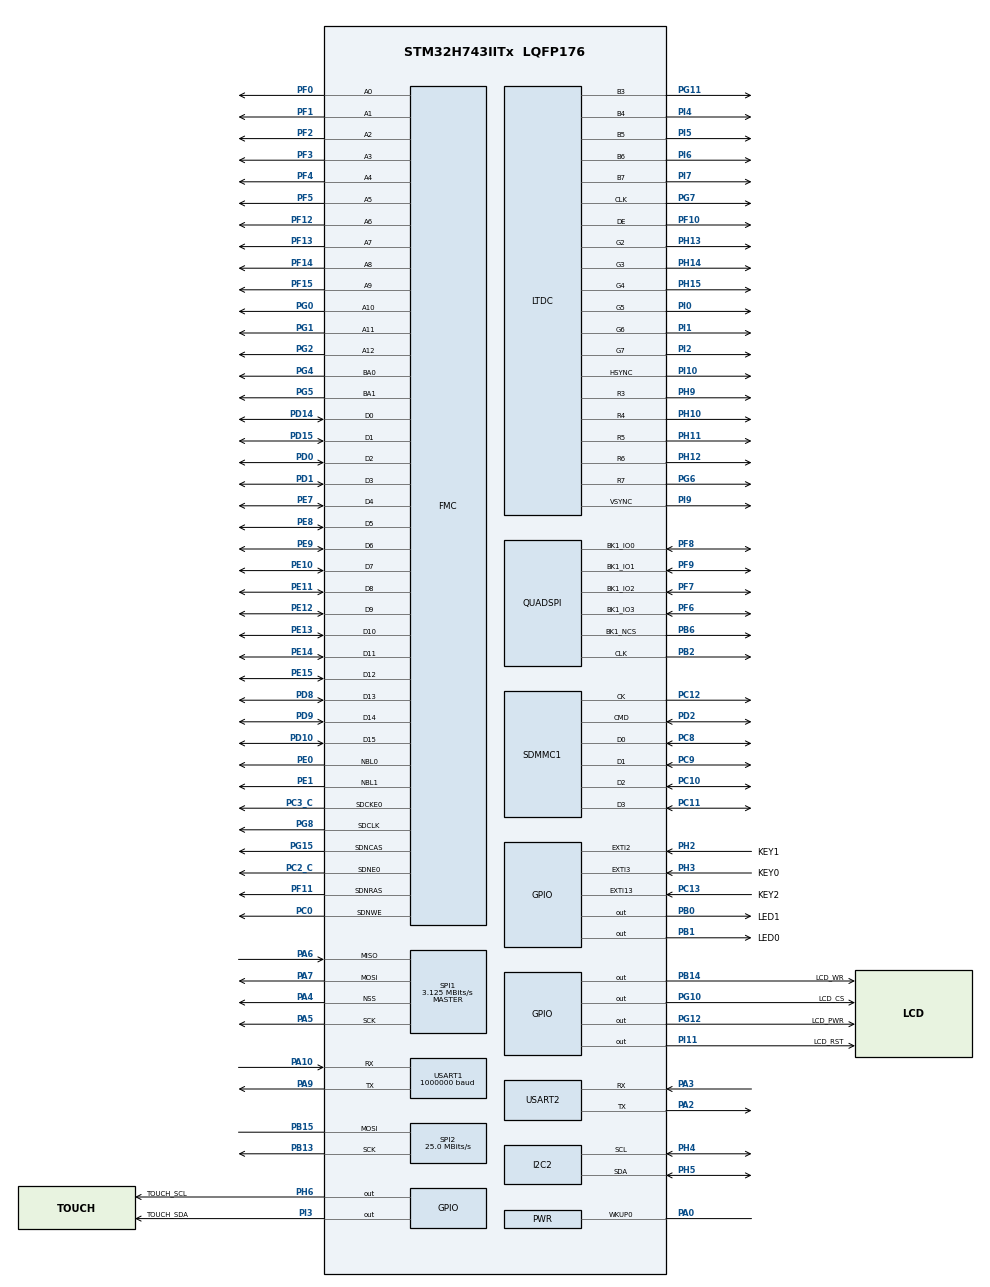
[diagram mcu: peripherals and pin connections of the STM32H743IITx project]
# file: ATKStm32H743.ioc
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CORTEX_M7.CPU_DCache=Enabled
CORTEX_M7.CPU_ICache=Enabled
Dma.I2C2_RX.0.Direction=DMA_PERIPH_TO_MEMORY
Dma.I2C2_RX.0.EventEnable=DISABLE
Dma.I2C2_RX.0.FIFOMode=DMA_FIFOMODE_DISABLE
Dma.I2C2_RX.0.Instance=DMA1_Stream2
Dma.I2C2_RX.0.MemDataAlignment=DMA_MDATAALIGN_BYTE
Dma.I2C2_RX.0.MemInc=DMA_MINC_ENABLE
Dma.I2C2_RX.0.Mode=DMA_NORMAL
Dma.I2C2_RX.0.PeriphDataAlignment=DMA_PDATAALIGN_BYTE
Dma.I2C2_RX.0.PeriphInc=DMA_PINC_DISABLE
Dma.I2C2_RX.0.Polarity=HAL_DMAMUX_REQ_GEN_RISING
Dma.I2C2_RX.0.Priority=DMA_PRIORITY_VERY_HIGH
Dma.I2C2_RX.0.RequestNumber=1
Dma.I2C2_RX.0.SignalID=NONE
Dma.I2C2_RX.0.SyncEnable=DISABLE
Dma.I2C2_RX.0.SyncPolarity=HAL_DMAMUX_SYNC_NO_EVENT
Dma.I2C2_RX.0.SyncRequestNumber=1
Dma.I2C2_RX.0.SyncSignalID=NONE
Dma.I2C2_TX.1.Direction=DMA_MEMORY_TO_PERIPH
Dma.I2C2_TX.1.EventEnable=DISABLE
Dma.I2C2_TX.1.FIFOMode=DMA_FIFOMODE_DISABLE
Dma.I2C2_TX.1.Instance=DMA1_Stream3
Dma.I2C2_TX.1.MemDataAlignment=DMA_MDATAALIGN_BYTE
Dma.I2C2_TX.1.MemInc=DMA_MINC_ENABLE
Dma.I2C2_TX.1.Mode=DMA_NORMAL
Dma.I2C2_TX.1.PeriphDataAlignment=DMA_PDATAALIGN_BYTE
Dma.I2C2_TX.1.PeriphInc=DMA_PINC_DISABLE
Dma.I2C2_TX.1.Polarity=HAL_DMAMUX_REQ_GEN_RISING
Dma.I2C2_TX.1.Priority=DMA_PRIORITY_LOW
Dma.I2C2_TX.1.RequestNumber=1
Dma.I2C2_TX.1.SignalID=NONE
Dma.I2C2_TX.1.SyncEnable=DISABLE
Dma.I2C2_TX.1.SyncPolarity=HAL_DMAMUX_SYNC_NO_EVENT
Dma.I2C2_TX.1.SyncRequestNumber=1
Dma.I2C2_TX.1.SyncSignalID=NONE
Dma.Request0=I2C2_RX
Dma.Request1=I2C2_TX
Dma.Request2=USART1_RX
Dma.Request3=USART1_TX
Dma.Request4=USART2_RX
Dma.Request5=USART2_TX
Dma.Request6=SPI2_RX
Dma.Request7=SPI2_TX
Dma.Request8=SPI1_RX
Dma.Request9=SPI1_TX
Dma.SPI1_RX.8.Direction=DMA_PERIPH_TO_MEMORY
Dma.SPI1_RX.8.EventEnable=DISABLE
Dma.SPI1_RX.8.FIFOMode=DMA_FIFOMODE_DISABLE
Dma.SPI1_RX.8.Instance=DMA2_Stream4
Dma.SPI1_RX.8.MemDataAlignment=DMA_MDATAALIGN_BYTE
Dma.SPI1_RX.8.MemInc=DMA_MINC_ENABLE
Dma.SPI1_RX.8.Mode=DMA_NORMAL
Dma.SPI1_RX.8.PeriphDataAlignment=DMA_PDATAALIGN_BYTE
Dma.SPI1_RX.8.PeriphInc=DMA_PINC_DISABLE
Dma.SPI1_RX.8.Polarity=HAL_DMAMUX_REQ_GEN_RISING
Dma.SPI1_RX.8.Priority=DMA_PRIORITY_MEDIUM
Dma.SPI1_RX.8.RequestNumber=1
Dma.SPI1_RX.8.SignalID=NONE
Dma.SPI1_RX.8.SyncEnable=DISABLE
Dma.SPI1_RX.8.SyncPolarity=HAL_DMAMUX_SYNC_NO_EVENT
Dma.SPI1_RX.8.SyncRequestNumber=1
Dma.SPI1_RX.8.SyncSignalID=NONE
Dma.SPI1_TX.9.Direction=DMA_MEMORY_TO_PERIPH
Dma.SPI1_TX.9.EventEnable=DISABLE
Dma.SPI1_TX.9.FIFOMode=DMA_FIFOMODE_DISABLE
Dma.SPI1_TX.9.Instance=DMA2_Stream5
Dma.SPI1_TX.9.MemDataAlignment=DMA_MDATAALIGN_BYTE
Dma.SPI1_TX.9.MemInc=DMA_MINC_ENABLE
Dma.SPI1_TX.9.Mode=DMA_NORMAL
Dma.SPI1_TX.9.PeriphDataAlignment=DMA_PDATAALIGN_BYTE
Dma.SPI1_TX.9.PeriphInc=DMA_PINC_DISABLE
Dma.SPI1_TX.9.Polarity=HAL_DMAMUX_REQ_GEN_RISING
Dma.SPI1_TX.9.Priority=DMA_PRIORITY_MEDIUM
Dma.SPI1_TX.9.RequestNumber=1
Dma.SPI1_TX.9.SignalID=NONE
Dma.SPI1_TX.9.SyncEnable=DISABLE
Dma.SPI1_TX.9.SyncPolarity=HAL_DMAMUX_SYNC_NO_EVENT
Dma.SPI1_TX.9.SyncRequestNumber=1
Dma.SPI1_TX.9.SyncSignalID=NONE
Dma.SPI2_RX.6.Direction=DMA_PERIPH_TO_MEMORY
Dma.SPI2_RX.6.EventEnable=DISABLE
Dma.SPI2_RX.6.FIFOMode=DMA_FIFOMODE_DISABLE
Dma.SPI2_RX.6.Instance=DMA2_Stream2
Dma.SPI2_RX.6.MemDataAlignment=DMA_MDATAALIGN_BYTE
Dma.SPI2_RX.6.MemInc=DMA_MINC_ENABLE
Dma.SPI2_RX.6.Mode=DMA_NORMAL
Dma.SPI2_RX.6.PeriphDataAlignment=DMA_PDATAALIGN_BYTE
Dma.SPI2_RX.6.PeriphInc=DMA_PINC_DISABLE
Dma.SPI2_RX.6.Polarity=HAL_DMAMUX_REQ_GEN_RISING
Dma.SPI2_RX.6.Priority=DMA_PRIORITY_MEDIUM
Dma.SPI2_RX.6.RequestNumber=1
Dma.SPI2_RX.6.SignalID=NONE
Dma.SPI2_RX.6.SyncEnable=DISABLE
Dma.SPI2_RX.6.SyncPolarity=HAL_DMAMUX_SYNC_NO_EVENT
Dma.SPI2_RX.6.SyncRequestNumber=1
Dma.SPI2_RX.6.SyncSignalID=NONE
Dma.SPI2_TX.7.Direction=DMA_MEMORY_TO_PERIPH
Dma.SPI2_TX.7.EventEnable=DISABLE
Dma.SPI2_TX.7.FIFOMode=DMA_FIFOMODE_DISABLE
Dma.SPI2_TX.7.Instance=DMA2_Stream3
Dma.SPI2_TX.7.MemDataAlignment=DMA_MDATAALIGN_BYTE
Dma.SPI2_TX.7.MemInc=DMA_MINC_ENABLE
Dma.SPI2_TX.7.Mode=DMA_NORMAL
Dma.SPI2_TX.7.PeriphDataAlignment=DMA_PDATAALIGN_BYTE
Dma.SPI2_TX.7.PeriphInc=DMA_PINC_DISABLE
Dma.SPI2_TX.7.Polarity=HAL_DMAMUX_REQ_GEN_RISING
Dma.SPI2_TX.7.Priority=DMA_PRIORITY_MEDIUM
Dma.SPI2_TX.7.RequestNumber=1
Dma.SPI2_TX.7.SignalID=NONE
Dma.SPI2_TX.7.SyncEnable=DISABLE
Dma.SPI2_TX.7.SyncPolarity=HAL_DMAMUX_SYNC_NO_EVENT
Dma.SPI2_TX.7.SyncRequestNumber=1
Dma.SPI2_TX.7.SyncSignalID=NONE
Dma.USART1_RX.2.Direction=DMA_PERIPH_TO_MEMORY
Dma.USART1_RX.2.EventEnable=DISABLE
Dma.USART1_RX.2.FIFOMode=DMA_FIFOMODE_DISABLE
Dma.USART1_RX.2.Instance=DMA1_Stream0
Dma.USART1_RX.2.MemDataAlignment=DMA_MDATAALIGN_BYTE
Dma.USART1_RX.2.MemInc=DMA_MINC_ENABLE
Dma.USART1_RX.2.Mode=DMA_CIRCULAR
Dma.USART1_RX.2.PeriphDataAlignment=DMA_PDATAALIGN_BYTE
Dma.USART1_RX.2.PeriphInc=DMA_PINC_DISABLE
Dma.USART1_RX.2.Polarity=HAL_DMAMUX_REQ_GEN_RISING
Dma.USART1_RX.2.Priority=DMA_PRIORITY_MEDIUM
Dma.USART1_RX.2.RequestNumber=1
Dma.USART1_RX.2.SignalID=NONE
Dma.USART1_RX.2.SyncEnable=DISABLE
Dma.USART1_RX.2.SyncPolarity=HAL_DMAMUX_SYNC_NO_EVENT
Dma.USART1_RX.2.SyncRequestNumber=1
Dma.USART1_RX.2.SyncSignalID=NONE
Dma.USART1_TX.3.Direction=DMA_MEMORY_TO_PERIPH
Dma.USART1_TX.3.EventEnable=DISABLE
Dma.USART1_TX.3.FIFOMode=DMA_FIFOMODE_DISABLE
Dma.USART1_TX.3.Instance=DMA1_Stream1
Dma.USART1_TX.3.MemDataAlignment=DMA_MDATAALIGN_BYTE
Dma.USART1_TX.3.MemInc=DMA_MINC_ENABLE
Dma.USART1_TX.3.Mode=DMA_NORMAL
Dma.USART1_TX.3.PeriphDataAlignment=DMA_PDATAALIGN_BYTE
Dma.USART1_TX.3.PeriphInc=DMA_PINC_DISABLE
Dma.USART1_TX.3.Polarity=HAL_DMAMUX_REQ_GEN_RISING
Dma.USART1_TX.3.Priority=DMA_PRIORITY_LOW
Dma.USART1_TX.3.RequestNumber=1
Dma.USART1_TX.3.SignalID=NONE
Dma.USART1_TX.3.SyncEnable=DISABLE
Dma.USART1_TX.3.SyncPolarity=HAL_DMAMUX_SYNC_NO_EVENT
Dma.USART1_TX.3.SyncRequestNumber=1
Dma.USART1_TX.3.SyncSignalID=NONE
Dma.USART2_RX.4.Direction=DMA_PERIPH_TO_MEMORY
Dma.USART2_RX.4.EventEnable=DISABLE
Dma.USART2_RX.4.FIFOMode=DMA_FIFOMODE_DISABLE
Dma.USART2_RX.4.Instance=DMA2_Stream0
Dma.USART2_RX.4.MemDataAlignment=DMA_MDATAALIGN_BYTE
Dma.USART2_RX.4.MemInc=DMA_MINC_ENABLE
Dma.USART2_RX.4.Mode=DMA_CIRCULAR
Dma.USART2_RX.4.PeriphDataAlignment=DMA_PDATAALIGN_BYTE
Dma.USART2_RX.4.PeriphInc=DMA_PINC_DISABLE
Dma.USART2_RX.4.Polarity=HAL_DMAMUX_REQ_GEN_RISING
Dma.USART2_RX.4.Priority=DMA_PRIORITY_VERY_HIGH
Dma.USART2_RX.4.RequestNumber=1
Dma.USART2_RX.4.SignalID=NONE
Dma.USART2_RX.4.SyncEnable=DISABLE
Dma.USART2_RX.4.SyncPolarity=HAL_DMAMUX_SYNC_NO_EVENT
Dma.USART2_RX.4.SyncRequestNumber=1
Dma.USART2_RX.4.SyncSignalID=NONE
Dma.USART2_TX.5.Direction=DMA_MEMORY_TO_PERIPH
Dma.USART2_TX.5.EventEnable=DISABLE
Dma.USART2_TX.5.FIFOMode=DMA_FIFOMODE_DISABLE
Dma.USART2_TX.5.Instance=DMA2_Stream1
Dma.USART2_TX.5.MemDataAlignment=DMA_MDATAALIGN_BYTE
Dma.USART2_TX.5.MemInc=DMA_MINC_ENABLE
Dma.USART2_TX.5.Mode=DMA_NORMAL
Dma.USART2_TX.5.PeriphDataAlignment=DMA_PDATAALIGN_BYTE
Dma.USART2_TX.5.PeriphInc=DMA_PINC_DISABLE
Dma.USART2_TX.5.Polarity=HAL_DMAMUX_REQ_GEN_RISING
Dma.USART2_TX.5.Priority=DMA_PRIORITY_LOW
Dma.USART2_TX.5.RequestNumber=1
Dma.USART2_TX.5.SignalID=NONE
Dma.USART2_TX.5.SyncEnable=DISABLE
Dma.USART2_TX.5.SyncPolarity=HAL_DMAMUX_SYNC_NO_EVENT
Dma.USART2_TX.5.SyncRequestNumber=1
Dma.USART2_TX.5.SyncSignalID=NONE
FMC.CASLatency1=FMC_SDRAM_CAS_LATENCY_2
FMC.ColumnBitsNumber1=FMC_SDRAM_COLUMN_BITS_NUM_9
FMC.ExitSelfRefreshDelay1=8
FMC.LoadToActiveDelay1=2
FMC.RCDDelay1=2
FMC.RPDelay1=2
FMC.ReadBurst1=FMC_SDRAM_RBURST_ENABLE
FMC.RowCycleDelay1=6
FMC.SDClockPeriod1=FMC_SDRAM_CLOCK_PERIOD_2
FMC.SelfRefreshTime1=6
FMC.WriteRecoveryTime1=4
I2C2.Speed=50
I2C2.Timing=0x50404CFD
LTDC.ActiveW=272
LTDC.HBP=40
LTDC.HFP=5
LTDC.HSync=1
LTDC.PixelFormat_L0=LTDC_PIXEL_FORMAT_RGB565
LTDC.PixelFormat_L1=LTDC_PIXEL_FORMAT_RGB565
LTDC.VBP=8
LTDC.VFP=8
LTDC.VSync=1
Mcu.Family=STM32H7
Mcu.Name=STM32H743IITx
Mcu.Package=LQFP176
NVIC.DMA1_Stream0_IRQn=true\:4\:0\:true\:false\:true\:false\:true\:true
NVIC.DMA1_Stream1_IRQn=true\:4\:1\:true\:false\:true\:false\:true\:true
NVIC.DMA1_Stream2_IRQn=true\:3\:0\:true\:false\:true\:false\:true\:true
NVIC.DMA1_Stream3_IRQn=true\:3\:0\:true\:false\:true\:false\:true\:true
NVIC.DMA2_Stream0_IRQn=true\:2\:0\:true\:false\:true\:false\:true\:true
NVIC.DMA2_Stream1_IRQn=true\:2\:1\:true\:false\:true\:false\:true\:true
NVIC.DMA2_Stream2_IRQn=true\:3\:0\:true\:false\:true\:false\:true\:true
NVIC.DMA2_Stream3_IRQn=true\:3\:0\:true\:false\:true\:false\:true\:true
NVIC.DMA2_Stream4_IRQn=true\:3\:0\:true\:false\:true\:false\:true\:true
NVIC.DMA2_Stream5_IRQn=true\:3\:0\:true\:false\:true\:false\:true\:true
NVIC.EXTI15_10_IRQn=true\:6\:0\:true\:false\:true\:true\:true\:true
NVIC.EXTI2_IRQn=true\:6\:0\:true\:false\:true\:true\:true\:true
NVIC.EXTI3_IRQn=true\:6\:0\:true\:false\:true\:true\:true\:true
NVIC.I2C2_ER_IRQn=true\:3\:0\:true\:false\:true\:true\:true\:true
NVIC.I2C2_EV_IRQn=true\:3\:0\:true\:false\:true\:true\:true\:true
NVIC.PVD_AVD_IRQn=true\:6\:0\:true\:false\:true\:true\:true\:true
NVIC.PriorityGroup=NVIC_PRIORITYGROUP_3
NVIC.QUADSPI_IRQn=true\:2\:0\:true\:false\:true\:true\:true\:true
NVIC.SDMMC1_IRQn=true\:2\:0\:true\:false\:true\:true\:true\:true
NVIC.SPI1_IRQn=true\:3\:0\:true\:false\:true\:false\:true\:true
NVIC.SPI2_IRQn=true\:3\:0\:true\:false\:true\:false\:true\:true
NVIC.USART1_IRQn=true\:4\:0\:true\:false\:true\:true\:true\:true
NVIC.USART2_IRQn=true\:2\:0\:true\:false\:true\:true\:true\:true
NVIC.WAKEUP_PIN_IRQn=true\:1\:1\:true\:false\:true\:true\:true\:true
PA0.Mode=WakeUp0
PA0.Signal=PWR_WKUP0
PA10.GPIO_Speed=GPIO_SPEED_FREQ_VERY_HIGH
PA10.Mode=Asynchronous
PA10.Signal=USART1_RX
PA13\ (JTMS/SWDIO).Mode=JTAG_5_pins
PA13\ (JTMS/SWDIO).Signal=DEBUG_JTMS-SWDIO
PA14\ (JTCK/SWCLK).Mode=JTAG_5_pins
PA14\ (JTCK/SWCLK).Signal=DEBUG_JTCK-SWCLK
PA15\ (JTDI).Mode=JTAG_5_pins
PA15\ (JTDI).Signal=DEBUG_JTDI
PA2.GPIO_Speed=GPIO_SPEED_FREQ_VERY_HIGH
PA2.Mode=Asynchronous
PA2.Signal=USART2_TX
PA3.GPIO_Speed=GPIO_SPEED_FREQ_VERY_HIGH
PA3.Mode=Asynchronous
PA3.Signal=USART2_RX
PA4.Mode=NSS_Signal_Hard_Output
PA4.Signal=SPI1_NSS
PA5.Mode=Full_Duplex_Master
PA5.Signal=SPI1_SCK
PA6.Mode=Full_Duplex_Master
PA6.Signal=SPI1_MISO
PA7.Mode=Full_Duplex_Master
PA7.Signal=SPI1_MOSI
PA9.GPIO_Speed=GPIO_SPEED_FREQ_VERY_HIGH
PA9.Mode=Asynchronous
PA9.Signal=USART1_TX
PB0.GPIO_Label=LED1
PB0.PinState=GPIO_PIN_SET
PB0.Signal=GPIO_Output
PB1.GPIO_Label=LED0
PB1.PinState=GPIO_PIN_SET
PB1.Signal=GPIO_Output
PB13.GPIO_Speed=GPIO_SPEED_FREQ_VERY_HIGH
PB13.Mode=Simplex_Bidirectional_Master
PB13.Signal=SPI2_SCK
PB14.GPIO_Label=LCD_WR
PB14.GPIO_Speed=GPIO_SPEED_FREQ_VERY_HIGH
PB14.Signal=GPIO_Output
PB15.GPIO_Speed=GPIO_SPEED_FREQ_VERY_HIGH
PB15.Mode=Simplex_Bidirectional_Master
PB15.Signal=SPI2_MOSI
PB2.GPIO_Speed=GPIO_SPEED_FREQ_VERY_HIGH
PB2.Mode=Single Bank 1
PB2.Signal=QUADSPI_CLK
PB3\ (JTDO/TRACESWO).Mode=JTAG_5_pins
PB3\ (JTDO/TRACESWO).Signal=DEBUG_JTDO-SWO
PB4\ (NJTRST).Mode=JTAG_5_pins
PB4\ (NJTRST).Signal=DEBUG_JTRST
PB6.GPIO_Speed=GPIO_SPEED_FREQ_VERY_HIGH
PB6.Mode=Single Bank 1
PB6.Signal=QUADSPI_BK1_NCS
PC0.Signal=FMC_SDNWE
PC10.Mode=SD_4_bits_Wide_bus
PC10.Signal=SDMMC1_D2
PC11.Mode=SD_4_bits_Wide_bus
PC11.Signal=SDMMC1_D3
PC12.Mode=SD_4_bits_Wide_bus
PC12.Signal=SDMMC1_CK
PC13.GPIO_Label=KEY2
PC13.GPIO_ModeDefaultEXTI=GPIO_MODE_IT_FALLING
PC13.GPIO_PuPd=GPIO_PULLUP
PC13.Signal=GPXTI13
PC14-OSC32_IN\ (OSC32_IN).Mode=LSE-External-Oscillator
PC14-OSC32_IN\ (OSC32_IN).Signal=RCC_OSC32_IN
PC15-OSC32_OUT\ (OSC32_OUT).Mode=LSE-External-Oscillator
PC15-OSC32_OUT\ (OSC32_OUT).Signal=RCC_OSC32_OUT
PC2_C.Mode=SdramChipSelect1_1
PC2_C.Signal=FMC_SDNE0
PC3_C.Mode=SdramChipSelect1_1
PC3_C.Signal=FMC_SDCKE0
PC8.Mode=SD_4_bits_Wide_bus
PC8.Signal=SDMMC1_D0
PC9.Mode=SD_4_bits_Wide_bus
PC9.Signal=SDMMC1_D1
PD0.Signal=FMC_D2_DA2
PD1.Signal=FMC_D3_DA3
PD10.Signal=FMC_D15_DA15
PD14.Signal=FMC_D0_DA0
PD15.Signal=FMC_D1_DA1
PD2.Mode=SD_4_bits_Wide_bus
PD2.Signal=SDMMC1_CMD
PD6.Signal=FMC_NWAIT
PD8.Signal=FMC_D13_DA13
PD9.Signal=FMC_D14_DA14
PE0.Signal=FMC_NBL0
PE1.Signal=FMC_NBL1
PE10.Signal=FMC_D7_DA7
PE11.Signal=FMC_D8_DA8
PE12.Signal=FMC_D9_DA9
PE13.Signal=FMC_D10_DA10
PE14.Signal=FMC_D11_DA11
PE15.Signal=FMC_D12_DA12
PE7.Signal=FMC_D4_DA4
PE8.Signal=FMC_D5_DA5
PE9.Signal=FMC_D6_DA6
PF0.Signal=FMC_A0
PF1.Signal=FMC_A1
PF10.Mode=RGB565
PF10.Signal=LTDC_DE
PF11.Signal=FMC_SDNRAS
PF12.Signal=FMC_A6
PF13.Signal=FMC_A7
PF14.Signal=FMC_A8
PF15.Signal=FMC_A9
PF2.Signal=FMC_A2
PF3.Signal=FMC_A3
PF4.Signal=FMC_A4
PF5.Signal=FMC_A5
PF6.GPIO_Speed=GPIO_SPEED_FREQ_VERY_HIGH
PF6.Mode=Single Bank 1
PF6.Signal=QUADSPI_BK1_IO3
PF7.GPIO_Speed=GPIO_SPEED_FREQ_VERY_HIGH
PF7.Mode=Single Bank 1
PF7.Signal=QUADSPI_BK1_IO2
PF8.GPIO_Speed=GPIO_SPEED_FREQ_VERY_HIGH
PF8.Mode=Single Bank 1
PF8.Signal=QUADSPI_BK1_IO0
PF9.GPIO_Speed=GPIO_SPEED_FREQ_VERY_HIGH
PF9.Mode=Single Bank 1
PF9.Signal=QUADSPI_BK1_IO1
PG0.Signal=FMC_A10
PG1.Signal=FMC_A11
PG10.GPIO_Label=LCD_CS
PG10.GPIO_Speed=GPIO_SPEED_FREQ_VERY_HIGH
PG10.Signal=GPIO_Output
PG11.Mode=RGB565
PG11.Signal=LTDC_B3
PG12.GPIO_Label=LCD_PWR
PG12.GPIO_Speed=GPIO_SPEED_FREQ_VERY_HIGH
PG12.Signal=GPIO_Output
PG15.Signal=FMC_SDNCAS
PG2.Signal=FMC_A12
PG4.Signal=FMC_A14_BA0
PG5.Signal=FMC_A15_BA1
PG6.Mode=RGB565
PG6.Signal=LTDC_R7
PG7.Mode=RGB565
PG7.Signal=LTDC_CLK
PG8.Signal=FMC_SDCLK
PH0-OSC_IN\ (PH0).Mode=HSE-External-Oscillator
PH0-OSC_IN\ (PH0).Signal=RCC_OSC_IN
PH1-OSC_OUT\ (PH1).Mode=HSE-External-Oscillator
PH1-OSC_OUT\ (PH1).Signal=RCC_OSC_OUT
PH10.Mode=RGB565
PH10.Signal=LTDC_R4
PH11.Mode=RGB565
PH11.Signal=LTDC_R5
PH12.Mode=RGB565
PH12.Signal=LTDC_R6
PH13.Mode=RGB565
PH13.Signal=LTDC_G2
PH14.Mode=RGB565
PH14.Signal=LTDC_G3
PH15.Mode=RGB565
PH15.Signal=LTDC_G4
PH2.GPIO_Label=KEY1
PH2.GPIO_ModeDefaultEXTI=GPIO_MODE_IT_FALLING
PH2.GPIO_PuPd=GPIO_PULLUP
PH2.Signal=GPXTI2
PH3.GPIO_Label=KEY0
PH3.GPIO_ModeDefaultEXTI=GPIO_MODE_IT_FALLING
PH3.GPIO_PuPd=GPIO_PULLUP
PH3.Signal=GPXTI3
PH4.GPIO_Pu=GPIO_PULLUP
PH4.Mode=I2C
PH4.Signal=I2C2_SCL
PH5.GPIO_Pu=GPIO_PULLUP
PH5.Mode=I2C
PH5.Signal=I2C2_SDA
PH6.GPIO_Label=TOUCH_SCL
PH6.GPIO_ModeDefaultOutputPP=GPIO_MODE_OUTPUT_OD
PH6.GPIO_PuPd=GPIO_PULLUP
PH6.GPIO_Speed=GPIO_SPEED_FREQ_VERY_HIGH
PH6.PinState=GPIO_PIN_SET
PH6.Signal=GPIO_Output
PH9.Mode=RGB565
PH9.Signal=LTDC_R3
PI0.Mode=RGB565
PI0.Signal=LTDC_G5
PI1.Mode=RGB565
PI1.Signal=LTDC_G6
PI10.Mode=RGB565
PI10.Signal=LTDC_HSYNC
PI11.GPIO_Label=LCD_RST
PI11.GPIO_Speed=GPIO_SPEED_FREQ_VERY_HIGH
PI11.Signal=GPIO_Output
PI2.Mode=RGB565
PI2.Signal=LTDC_G7
PI3.GPIO_Label=TOUCH_SDA
PI3.GPIO_ModeDefaultOutputPP=GPIO_MODE_OUTPUT_OD
PI3.GPIO_PuPd=GPIO_PULLUP
PI3.GPIO_Speed=GPIO_SPEED_FREQ_VERY_HIGH
PI3.PinState=GPIO_PIN_SET
PI3.Signal=GPIO_Output
PI4.Mode=RGB565
PI4.Signal=LTDC_B4
PI5.Mode=RGB565
PI5.Signal=LTDC_B5
PI6.Mode=RGB565
PI6.Signal=LTDC_B6
PI7.Mode=RGB565
PI7.Signal=LTDC_B7
PI9.Mode=RGB565
PI9.Signal=LTDC_VSYNC
ProjectManager.HeapSize=0x200
ProjectManager.StackSize=0x400
ProjectManager.TargetToolchain=Makefile
QUADSPI.ChipSelectHighTime=QSPI_CS_HIGH_TIME_5_CYCLE
QUADSPI.ClockPrescaler=1
QUADSPI.FifoThreshold=4
QUADSPI.FlashSize=24
QUADSPI.SampleShifting=QSPI_SAMPLE_SHIFTING_HALFCYCLE
RCC.ADCFreq_Value=200000000
RCC.APB1Freq_Value=100000000
RCC.APB2Freq_Value=100000000
RCC.APB3Freq_Value=100000000
RCC.APB4Freq_Value=100000000
RCC.CortexFreq_Value=400000000
RCC.D1PPRE=RCC_APB3_DIV2
RCC.D2PPRE1=RCC_APB1_DIV2
RCC.D2PPRE2=RCC_APB2_DIV2
RCC.D3PPRE=RCC_APB4_DIV2
RCC.DIVM1=5
RCC.DIVM2=5
RCC.DIVM3=25
RCC.DIVN1=160
RCC.DIVN2=80
RCC.DIVN3=150
RCC.DIVQ1=4
RCC.DIVQ2=4
RCC.HCLKFreq_Value=200000000
RCC.HPRE=RCC_HCLK_DIV2
RCC.LPUART1CLockSelection=RCC_LPUART1CLKSOURCE_CSI
RCC.PLLSourceVirtual=RCC_PLLSOURCE_HSE
RCC.SYSCLKFreq_VALUE=400000000
RCC.SYSCLKSource=RCC_SYSCLKSOURCE_PLLCLK
RCC.USBFreq_Value=200000000
SDMMC1.ClockDiv=4
SH.FMC_A0.0=FMC_A0,13b-sda1
SH.FMC_A1.0=FMC_A1,13b-sda1
SH.FMC_A10.0=FMC_A10,13b-sda1
SH.FMC_A11.0=FMC_A11,13b-sda1
SH.FMC_A12.0=FMC_A12,13b-sda1
SH.FMC_A14_BA0.0=FMC_BA0,FourSdramBanks1
SH.FMC_A15_BA1.0=FMC_BA1,FourSdramBanks1
SH.FMC_A2.0=FMC_A2,13b-sda1
SH.FMC_A3.0=FMC_A3,13b-sda1
SH.FMC_A4.0=FMC_A4,13b-sda1
SH.FMC_A5.0=FMC_A5,13b-sda1
SH.FMC_A6.0=FMC_A6,13b-sda1
SH.FMC_A7.0=FMC_A7,13b-sda1
SH.FMC_A8.0=FMC_A8,13b-sda1
SH.FMC_A9.0=FMC_A9,13b-sda1
SH.FMC_D0_DA0.0=FMC_D0,sd-16b-d1
SH.FMC_D10_DA10.0=FMC_D10,sd-16b-d1
SH.FMC_D11_DA11.0=FMC_D11,sd-16b-d1
SH.FMC_D12_DA12.0=FMC_D12,sd-16b-d1
SH.FMC_D13_DA13.0=FMC_D13,sd-16b-d1
SH.FMC_D14_DA14.0=FMC_D14,sd-16b-d1
SH.FMC_D15_DA15.0=FMC_D15,sd-16b-d1
SH.FMC_D1_DA1.0=FMC_D1,sd-16b-d1
SH.FMC_D2_DA2.0=FMC_D2,sd-16b-d1
SH.FMC_D3_DA3.0=FMC_D3,sd-16b-d1
SH.FMC_D4_DA4.0=FMC_D4,sd-16b-d1
SH.FMC_D5_DA5.0=FMC_D5,sd-16b-d1
SH.FMC_D6_DA6.0=FMC_D6,sd-16b-d1
SH.FMC_D7_DA7.0=FMC_D7,sd-16b-d1
SH.FMC_D8_DA8.0=FMC_D8,sd-16b-d1
SH.FMC_D9_DA9.0=FMC_D9,sd-16b-d1
SH.FMC_NBL0.0=FMC_NBL0,Sd2ByteEnable1
SH.FMC_NBL1.0=FMC_NBL1,Sd2ByteEnable1
SH.FMC_NWAIT.0=FMC_NWAIT
SH.FMC_SDCLK.0=FMC_SDCLK,13b-sda1
SH.FMC_SDNCAS.0=FMC_SDNCAS,13b-sda1
SH.FMC_SDNRAS.0=FMC_SDNRAS,13b-sda1
SH.FMC_SDNWE.0=FMC_SDNWE,13b-sda1
SPI1.BaudRatePrescaler=SPI_BAUDRATEPRESCALER_64
SPI1.CalculateBaudRate=3.125 MBits/s
SPI1.DataSize=SPI_DATASIZE_8BIT
SPI1.Direction=SPI_DIRECTION_2LINES
SPI1.MasterKeepIOState=SPI_MASTER_KEEP_IO_STATE_ENABLE
SPI1.MasterSSIdleness=SPI_MASTER_SS_IDLENESS_01CYCLE
SPI1.Mode=SPI_MODE_MASTER
SPI1.NSSPMode=SPI_NSS_PULSE_DISABLE
SPI1.VirtualNSS=VM_NSSHARD
SPI1.VirtualType=VM_MASTER
SPI2.BaudRatePrescaler=SPI_BAUDRATEPRESCALER_8
SPI2.CLKPhase=SPI_PHASE_2EDGE
SPI2.CLKPolarity=SPI_POLARITY_HIGH
SPI2.CalculateBaudRate=25.0 MBits/s
SPI2.DataSize=SPI_DATASIZE_8BIT
SPI2.Direction=SPI_DIRECTION_1LINE
SPI2.MasterKeepIOState=SPI_MASTER_KEEP_IO_STATE_ENABLE
SPI2.MasterSSIdleness=SPI_MASTER_SS_IDLENESS_00CYCLE
SPI2.Mode=SPI_MODE_MASTER
SPI2.NSSPMode=SPI_NSS_PULSE_DISABLE
SPI2.VirtualType=VM_MASTER
USART1.BaudRate=1000000
USART1.DMADisableonRxErrorParam=ADVFEATURE_DMA_ENABLEONRXERROR
USART1.VirtualMode-Asynchronous=VM_ASYNC
USART2.VirtualMode-Asynchronous=VM_ASYNC
VP_CRC_VS_CRC.Mode=CRC_Activate
VP_RNG_VS_RNG.Mode=RNG_Activate
board=custom

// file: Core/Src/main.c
/* USER CODE BEGIN Header */
/**
  ******************************************************************************
  * @file           : main.c
  * @brief          : Main program body
  ******************************************************************************
  * @author
  * + 隐星魂 (Roy Sun) <xwos@xwos.tech>
  * @copyright
  * + Copyright © 2015 xwos.tech, All Rights Reserved.
  * > Licensed under the Apache License, Version 2.0 (the "License");
  * > you may not use this file except in compliance with the License.
  * > You may obtain a copy of the License at
  * >
  * >         http://www.apache.org/licenses/LICENSE-2.0
  * >
  * > Unless required by applicable law or agreed to in writing, software
  * > distributed under the License is distributed on an "AS IS" BASIS,
  * > WITHOUT WARRANTIES OR CONDITIONS OF ANY KIND, either express or implied.
  * > See the License for the specific language governing permissions and
  * > limitations under the License.
  *
  ******************************************************************************
  */
/* USER CODE END Header */
#include "main.h"
#include "crc.h"
#include "dma.h"
#include "i2c.h"
#include "ltdc.h"
#include "quadspi.h"
#include "rng.h"
#include "sdmmc.h"
#include "spi.h"
#include "usart.h"
#include "gpio.h"
#include "fmc.h"

void SystemClock_Config(void);

int main(void)
{

  /* Enable I-Cache---------------------------------------------------------*/
  SCB_EnableICache();

  /* Enable D-Cache---------------------------------------------------------*/
  SCB_EnableDCache();

  /* MCU Configuration--------------------------------------------------------*/

  /* Reset of all peripherals, Initializes the Flash interface and the Systick. */
  HAL_Init();

  /* Configure the system clock */
  SystemClock_Config();

  /* Initialize all configured peripherals */
  MX_GPIO_Init();
  MX_DMA_Init();
  MX_CRC_Init();
  MX_FMC_Init();
  MX_I2C2_Init();
  MX_LTDC_Init();
  MX_QUADSPI_Init();
  MX_SDMMC1_SD_Init();
  MX_RNG_Init();
  MX_USART1_UART_Init();
  MX_USART2_UART_Init();
  MX_SPI2_Init();
  MX_SPI1_Init();

  /* Infinite loop */
  while (1)
  {

  }
}

void SystemClock_Config(void)
{
  RCC_OscInitTypeDef RCC_OscInitStruct = {0};
  RCC_ClkInitTypeDef RCC_ClkInitStruct = {0};

  /** Supply configuration update enable
  */
  HAL_PWREx_ConfigSupply(PWR_LDO_SUPPLY);

  /** Configure the main internal regulator output voltage
  */
  __HAL_PWR_VOLTAGESCALING_CONFIG(PWR_REGULATOR_VOLTAGE_SCALE1);

  while(!__HAL_PWR_GET_FLAG(PWR_FLAG_VOSRDY)) {}

  /** Macro to configure the PLL clock source
  */
  __HAL_RCC_PLL_PLLSOURCE_CONFIG(RCC_PLLSOURCE_HSE);

  /** Initializes the RCC Oscillators according to the specified parameters
  * in the RCC_OscInitTypeDef structure.
  */
  RCC_OscInitStruct.OscillatorType = RCC_OSCILLATORTYPE_HSI48|RCC_OSCILLATORTYPE_HSE;
  RCC_OscInitStruct.HSEState = RCC_HSE_ON;
  RCC_OscInitStruct.HSI48State = RCC_HSI48_ON;
  RCC_OscInitStruct.PLL.PLLState = RCC_PLL_ON;
  RCC_OscInitStruct.PLL.PLLSource = RCC_PLLSOURCE_HSE;
  RCC_OscInitStruct.PLL.PLLM = 5;
  RCC_OscInitStruct.PLL.PLLN = 160;
  RCC_OscInitStruct.PLL.PLLP = 2;
  RCC_OscInitStruct.PLL.PLLQ = 4;
  RCC_OscInitStruct.PLL.PLLR = 2;
  RCC_OscInitStruct.PLL.PLLRGE = RCC_PLL1VCIRANGE_2;
  RCC_OscInitStruct.PLL.PLLVCOSEL = RCC_PLL1VCOWIDE;
  RCC_OscInitStruct.PLL.PLLFRACN = 0;
  if (HAL_RCC_OscConfig(&RCC_OscInitStruct) != HAL_OK)
  {
    Error_Handler();
  }

  /** Initializes the CPU, AHB and APB buses clocks
  */
  RCC_ClkInitStruct.ClockType = RCC_CLOCKTYPE_HCLK|RCC_CLOCKTYPE_SYSCLK
                              |RCC_CLOCKTYPE_PCLK1|RCC_CLOCKTYPE_PCLK2
                              |RCC_CLOCKTYPE_D3PCLK1|RCC_CLOCKTYPE_D1PCLK1;
  RCC_ClkInitStruct.SYSCLKSource = RCC_SYSCLKSOURCE_PLLCLK;
  RCC_ClkInitStruct.SYSCLKDivider = RCC_SYSCLK_DIV1;
  RCC_ClkInitStruct.AHBCLKDivider = RCC_HCLK_DIV2;
  RCC_ClkInitStruct.APB3CLKDivider = RCC_APB3_DIV2;
  RCC_ClkInitStruct.APB1CLKDivider = RCC_APB1_DIV2;
  RCC_ClkInitStruct.APB2CLKDivider = RCC_APB2_DIV2;
  RCC_ClkInitStruct.APB4CLKDivider = RCC_APB4_DIV2;

  if (HAL_RCC_ClockConfig(&RCC_ClkInitStruct, FLASH_LATENCY_2) != HAL_OK)
  {
    Error_Handler();
  }
}

void Error_Handler(void)
{
  /* USER CODE BEGIN Error_Handler_Debug */
  /* User can add his own implementation to report the HAL error return state */
  __BKPT(0);
  /* USER CODE END Error_Handler_Debug */
}
